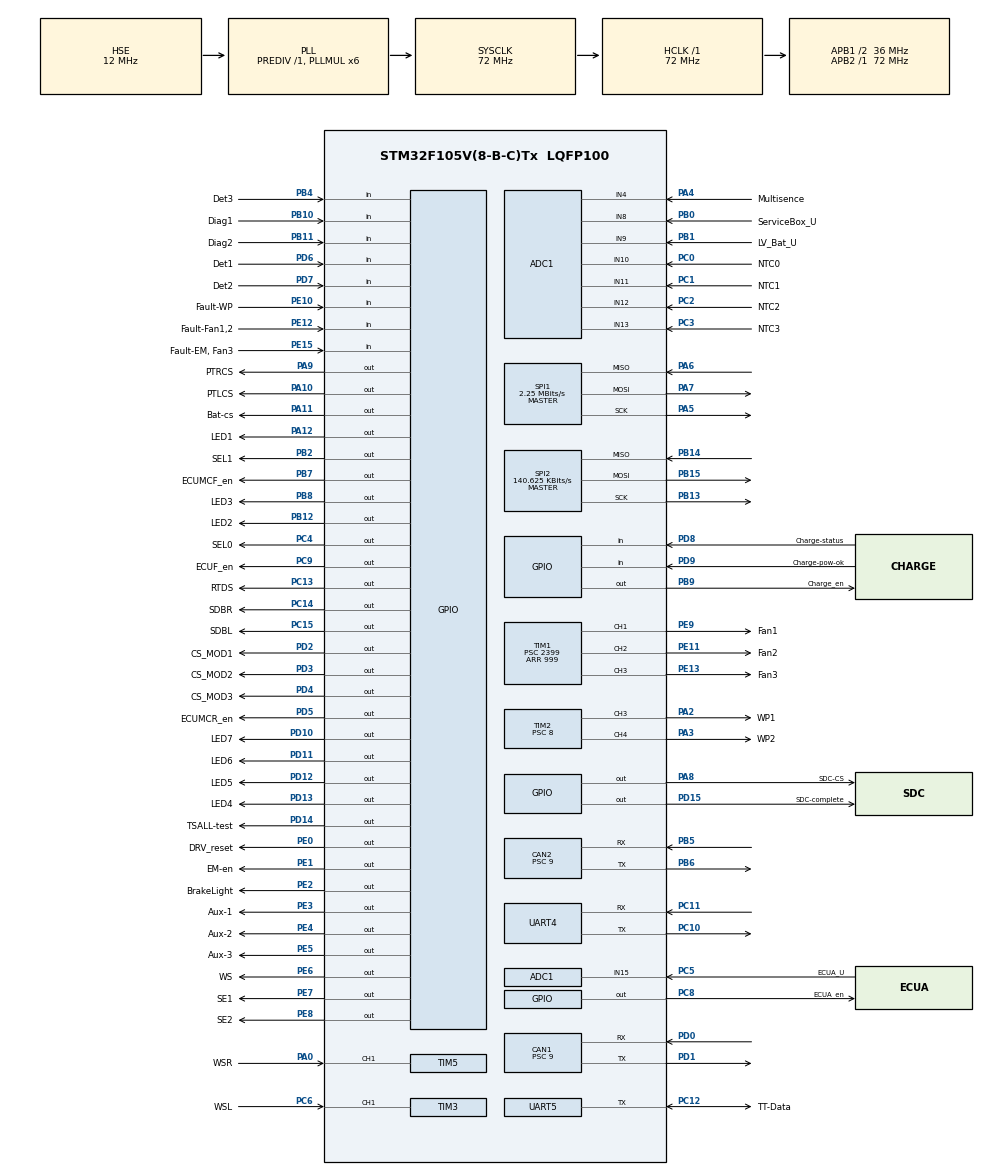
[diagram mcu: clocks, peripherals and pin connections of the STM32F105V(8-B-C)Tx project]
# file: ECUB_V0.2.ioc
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ADC1.Channel-10\#ChannelRegularConversion=ADC_CHANNEL_8
ADC1.Channel-11\#ChannelRegularConversion=ADC_CHANNEL_9
ADC1.Channel-12\#ChannelRegularConversion=ADC_CHANNEL_10
ADC1.Channel-13\#ChannelRegularConversion=ADC_CHANNEL_11
ADC1.Channel-14\#ChannelRegularConversion=ADC_CHANNEL_12
ADC1.Channel-15\#ChannelRegularConversion=ADC_CHANNEL_13
ADC1.Channel-16\#ChannelRegularConversion=ADC_CHANNEL_15
ADC1.Channel-9\#ChannelRegularConversion=ADC_CHANNEL_4
ADC1.ContinuousConvMode=ENABLE
ADC1.DataAlign=ADC_DATAALIGN_RIGHT
ADC1.DiscontinuousConvMode=DISABLE
ADC1.EnableAnalogWatchDog=false
ADC1.EnableRegularConversion=ENABLE
ADC1.ExternalTrigConv=ADC_SOFTWARE_START
ADC1.InjNumberOfConversion=0
ADC1.NbrOfConversion=8
ADC1.NbrOfConversionFlag=1
ADC1.Rank-10\#ChannelRegularConversion=2
ADC1.Rank-11\#ChannelRegularConversion=3
ADC1.Rank-12\#ChannelRegularConversion=4
ADC1.Rank-13\#ChannelRegularConversion=5
ADC1.Rank-14\#ChannelRegularConversion=6
ADC1.Rank-15\#ChannelRegularConversion=7
ADC1.Rank-16\#ChannelRegularConversion=8
ADC1.Rank-9\#ChannelRegularConversion=1
ADC1.SamplingTime-10\#ChannelRegularConversion=ADC_SAMPLETIME_1CYCLE_5
ADC1.SamplingTime-11\#ChannelRegularConversion=ADC_SAMPLETIME_1CYCLE_5
ADC1.SamplingTime-12\#ChannelRegularConversion=ADC_SAMPLETIME_1CYCLE_5
ADC1.SamplingTime-13\#ChannelRegularConversion=ADC_SAMPLETIME_1CYCLE_5
ADC1.SamplingTime-14\#ChannelRegularConversion=ADC_SAMPLETIME_1CYCLE_5
ADC1.SamplingTime-15\#ChannelRegularConversion=ADC_SAMPLETIME_1CYCLE_5
ADC1.SamplingTime-16\#ChannelRegularConversion=ADC_SAMPLETIME_1CYCLE_5
ADC1.SamplingTime-9\#ChannelRegularConversion=ADC_SAMPLETIME_1CYCLE_5
ADC1.ScanConvMode=ADC_SCAN_ENABLE
ADC1.master=1
CAN1.ABOM=ENABLE
CAN1.BS1=CAN_BS1_6TQ
CAN1.CalculateTimeBit=750
CAN1.CalculateTimeQuantum=250.0
CAN1.Mode=CAN_MODE_NORMAL
CAN1.Prescaler=9
CAN2.ABOM=ENABLE
CAN2.BS1=CAN_BS1_6TQ
CAN2.CalculateTimeBit=750
CAN2.CalculateTimeQuantum=250.0
CAN2.Mode=CAN_MODE_NORMAL
CAN2.Prescaler=9
Dma.ADC1.0.Direction=DMA_PERIPH_TO_MEMORY
Dma.ADC1.0.Instance=DMA1_Channel1
Dma.ADC1.0.MemDataAlignment=DMA_MDATAALIGN_HALFWORD
Dma.ADC1.0.MemInc=DMA_MINC_ENABLE
Dma.ADC1.0.Mode=DMA_CIRCULAR
Dma.ADC1.0.PeriphDataAlignment=DMA_PDATAALIGN_HALFWORD
Dma.ADC1.0.PeriphInc=DMA_PINC_DISABLE
Dma.ADC1.0.Priority=DMA_PRIORITY_HIGH
Dma.Request0=ADC1
Mcu.Family=STM32F1
Mcu.Name=STM32F105V(8-B-C)Tx
Mcu.Package=LQFP100
NVIC.CAN1_RX0_IRQn=true\:0\:0\:false\:false\:true\:true
NVIC.CAN1_RX1_IRQn=true\:0\:0\:false\:false\:true\:true
NVIC.CAN1_SCE_IRQn=true\:0\:0\:false\:false\:true\:true
NVIC.CAN1_TX_IRQn=true\:0\:0\:false\:false\:true\:true
NVIC.CAN2_RX0_IRQn=true\:0\:0\:false\:false\:true\:true
NVIC.CAN2_RX1_IRQn=true\:0\:0\:false\:false\:true\:true
NVIC.CAN2_SCE_IRQn=true\:0\:0\:false\:false\:true\:true
NVIC.CAN2_TX_IRQn=true\:0\:0\:false\:false\:true\:true
NVIC.DMA1_Channel1_IRQn=true\:0\:0\:false\:false\:true\:false
NVIC.PriorityGroup=NVIC_PRIORITYGROUP_4
NVIC.TIM1_BRK_IRQn=true\:0\:0\:false\:false\:true\:true
NVIC.TIM1_CC_IRQn=true\:0\:0\:false\:false\:true\:true
NVIC.TIM1_TRG_COM_IRQn=true\:0\:0\:false\:false\:true\:true
NVIC.TIM1_UP_IRQn=true\:0\:0\:false\:false\:true\:true
NVIC.TIM3_IRQn=true\:0\:0\:false\:false\:true\:true
NVIC.TIM5_IRQn=true\:0\:0\:false\:false\:true\:true
OSC_IN.Mode=HSE-External-Oscillator
OSC_IN.Signal=RCC_OSC_IN
OSC_OUT.Mode=HSE-External-Oscillator
OSC_OUT.Signal=RCC_OSC_OUT
PA0-WKUP.GPIO_Label=WSR
PA0-WKUP.Signal=S_TIM5_CH1
PA10.GPIO_Label=PTLCS
PA10.Signal=GPIO_Output
PA11.GPIO_Label=Bat-cs
PA11.Signal=GPIO_Output
PA12.GPIO_Label=LED1
PA12.Signal=GPIO_Output
PA13.GPIO_Label=SWDIO
PA13.Mode=Trace_Asynchronous_SW
PA13.Signal=SYS_JTMS-SWDIO
PA14.GPIO_Label=SWCLK
PA14.Mode=Trace_Asynchronous_SW
PA14.Signal=SYS_JTCK-SWCLK
PA2.GPIO_Label=WP1
PA2.Signal=S_TIM2_CH3
PA3.GPIO_Label=WP2
PA3.Signal=S_TIM2_CH4
PA4.GPIO_Label=Multisence
PA4.Signal=ADCx_IN4
PA5.Mode=Full_Duplex_Master
PA5.Signal=SPI1_SCK
PA6.Mode=Full_Duplex_Master
PA6.Signal=SPI1_MISO
PA7.Mode=Full_Duplex_Master
PA7.Signal=SPI1_MOSI
PA8.GPIO_Label=SDC-CS
PA8.Signal=GPIO_Output
PA9.GPIO_Label=PTRCS
PA9.Signal=GPIO_Output
PB0.GPIO_Label=ServiceBox_U
PB0.Signal=ADCx_IN8
PB1.GPIO_Label=LV_Bat_U
PB1.Signal=ADCx_IN9
PB10.GPIO_Label=Diag1
PB10.Signal=GPIO_Input
PB11.GPIO_Label=Diag2
PB11.Signal=GPIO_Input
PB12.GPIO_Label=LED2
PB12.Signal=GPIO_Output
PB13.Mode=Full_Duplex_Master
PB13.Signal=SPI2_SCK
PB14.Mode=Full_Duplex_Master
PB14.Signal=SPI2_MISO
PB15.Mode=Full_Duplex_Master
PB15.Signal=SPI2_MOSI
PB2.GPIO_Label=SEL1
PB2.Signal=GPIO_Output
PB3.GPIO_Label=SWO
PB3.Mode=Trace_Asynchronous_SW
PB3.Signal=SYS_TRACESWO
PB4.GPIO_Label=Det3
PB4.Signal=GPIO_Input
PB5.Mode=Slave
PB5.Signal=CAN2_RX
PB6.Mode=Slave
PB6.Signal=CAN2_TX
PB7.GPIO_Label=ECUMCF_en
PB7.Signal=GPIO_Output
PB8.GPIO_Label=LED3
PB8.Signal=GPIO_Output
PB9.GPIO_Label=Charge_en
PB9.Signal=GPIO_Output
PC0.GPIO_Label=NTC0
PC0.Signal=ADCx_IN10
PC1.GPIO_Label=NTC1
PC1.Signal=ADCx_IN11
PC10.Mode=Asynchronous
PC10.Signal=UART4_TX
PC11.Mode=Asynchronous
PC11.Signal=UART4_RX
PC12.GPIO_Label=TT-Data
PC12.Mode=Half_duplex(single_wire_mode)
PC12.Signal=UART5_TX
PC13-TAMPER-RTC.GPIO_Label=RTDS
PC13-TAMPER-RTC.Signal=GPIO_Output
PC14-OSC32_IN.GPIO_Label=SDBR
PC14-OSC32_IN.Signal=GPIO_Output
PC15-OSC32_OUT.GPIO_Label=SDBL
PC15-OSC32_OUT.Signal=GPIO_Output
PC2.GPIO_Label=NTC2
PC2.Signal=ADCx_IN12
PC3.GPIO_Label=NTC3
PC3.Signal=ADCx_IN13
PC4.GPIO_Label=SEL0
PC4.Signal=GPIO_Output
PC5.GPIO_Label=ECUA_U
PC5.Signal=ADCx_IN15
PC6.GPIO_Label=WSL
PC6.Signal=S_TIM3_CH1
PC8.GPIO_Label=ECUA_en
PC8.Signal=GPIO_Output
PC9.GPIO_Label=ECUF_en
PC9.Signal=GPIO_Output
PD0.Mode=Master
PD0.Signal=CAN1_RX
PD1.Mode=Master
PD1.Signal=CAN1_TX
PD10.GPIO_Label=LED7
PD10.Signal=GPIO_Output
PD11.GPIO_Label=LED6
PD11.Signal=GPIO_Output
PD12.GPIO_Label=LED5
PD12.Signal=GPIO_Output
PD13.GPIO_Label=LED4
PD13.Signal=GPIO_Output
PD14.GPIO_Label=TSALL-test
PD14.Signal=GPIO_Output
PD15.GPIO_Label=SDC-complete
PD15.Signal=GPIO_Output
PD2.GPIO_Label=CS_MOD1
PD2.Signal=GPIO_Output
PD3.GPIO_Label=CS_MOD2
PD3.Signal=GPIO_Output
PD4.GPIO_Label=CS_MOD3
PD4.Signal=GPIO_Output
PD5.GPIO_Label=ECUMCR_en
PD5.Signal=GPIO_Output
PD6.GPIO_Label=Det1
PD6.Signal=GPIO_Input
PD7.GPIO_Label=Det2
PD7.Signal=GPIO_Input
PD8.GPIO_Label=Charge-status
PD8.Signal=GPIO_Input
PD9.GPIO_Label=Charge-pow-ok
PD9.Signal=GPIO_Input
PE0.GPIO_Label=DRV_reset
PE0.Signal=GPIO_Output
PE1.GPIO_Label=EM-en
PE1.Signal=GPIO_Output
PE10.GPIO_Label=Fault-WP
PE10.Signal=GPIO_Input
PE11.GPIO_Label=Fan2
PE11.Signal=S_TIM1_CH2
PE12.GPIO_Label=Fault-Fan1,2
PE12.Signal=GPIO_Input
PE13.GPIO_Label=Fan3
PE13.Signal=S_TIM1_CH3
PE15.GPIO_Label=Fault-EM, Fan3
PE15.Signal=GPIO_Input
PE2.GPIO_Label=BrakeLight
PE2.Signal=GPIO_Output
PE3.GPIO_Label=Aux-1
PE3.Signal=GPIO_Output
PE4.GPIO_Label=Aux-2
PE4.Signal=GPIO_Output
PE5.GPIO_Label=Aux-3
PE5.Signal=GPIO_Output
PE6.GPIO_Label=WS
PE6.Signal=GPIO_Output
PE7.GPIO_Label=SE1
PE7.Signal=GPIO_Output
PE8.GPIO_Label=SE2
PE8.Signal=GPIO_Output
PE9.GPIO_Label=Fan1
PE9.Signal=S_TIM1_CH1
ProjectManager.HeapSize=0x200
ProjectManager.StackSize=0x400
ProjectManager.TargetToolchain=MDK-ARM V5
RCC.ADCPresc=RCC_ADCPCLK2_DIV6
RCC.AHBFreq_Value=72000000
RCC.APB1CLKDivider=RCC_HCLK_DIV2
RCC.APB1Freq_Value=36000000
RCC.APB1TimFreq_Value=72000000
RCC.APB2Freq_Value=72000000
RCC.APB2TimFreq_Value=72000000
RCC.HCLKFreq_Value=72000000
RCC.HSE_VALUE=12000000
RCC.PLLMUL=RCC_PLL_MUL6
RCC.PLLSourceVirtual=RCC_PLLSOURCE_HSE
RCC.SYSCLKFreq_VALUE=72000000
RCC.SYSCLKSource=RCC_SYSCLKSOURCE_PLLCLK
RCC.USBFreq_Value=48000000
SH.ADCx_IN10.0=ADC1_IN10,IN10
SH.ADCx_IN11.0=ADC1_IN11,IN11
SH.ADCx_IN12.0=ADC1_IN12,IN12
SH.ADCx_IN13.0=ADC1_IN13,IN13
SH.ADCx_IN15.0=ADC1_IN15,IN15
SH.ADCx_IN4.0=ADC1_IN4,IN4
SH.ADCx_IN8.0=ADC1_IN8,IN8
SH.ADCx_IN9.0=ADC1_IN9,IN9
SH.S_TIM1_CH1.0=TIM1_CH1,PWM Generation1 CH1
SH.S_TIM1_CH2.0=TIM1_CH2,PWM Generation2 CH2
SH.S_TIM1_CH3.0=TIM1_CH3,PWM Generation3 CH3
SH.S_TIM2_CH3.0=TIM2_CH3,PWM Generation3 CH3
SH.S_TIM2_CH4.0=TIM2_CH4,PWM Generation4 CH4
SH.S_TIM3_CH1.0=TIM3_CH1,Input_Capture1_from_TI1
SH.S_TIM5_CH1.0=TIM5_CH1,Input_Capture1_from_TI1
SPI1.BaudRatePrescaler=SPI_BAUDRATEPRESCALER_32
SPI1.CalculateBaudRate=2.25 MBits/s
SPI1.Direction=SPI_DIRECTION_2LINES
SPI1.Mode=SPI_MODE_MASTER
SPI1.VirtualType=VM_MASTER
SPI2.BaudRatePrescaler=SPI_BAUDRATEPRESCALER_256
SPI2.CalculateBaudRate=140.625 KBits/s
SPI2.DataSize=SPI_DATASIZE_16BIT
SPI2.Direction=SPI_DIRECTION_2LINES
SPI2.Mode=SPI_MODE_MASTER
SPI2.VirtualType=VM_MASTER
TIM1.Channel-PWM\ Generation1\ CH1=TIM_CHANNEL_1
TIM1.Channel-PWM\ Generation2\ CH2=TIM_CHANNEL_2
TIM1.Channel-PWM\ Generation3\ CH3=TIM_CHANNEL_3
TIM1.Period=999
TIM1.Prescaler=2399
TIM2.Channel-PWM\ Generation3\ CH3=TIM_CHANNEL_3
TIM2.Channel-PWM\ Generation4\ CH4=TIM_CHANNEL_4
TIM2.Period=999
TIM2.Prescaler=8
TIM3.Channel-Input_Capture1_from_TI1=TIM_CHANNEL_1
TIM3.Period=0xFFFF
TIM3.Prescaler=72
TIM5.Channel-Input_Capture1_from_TI1=TIM_CHANNEL_1
TIM5.Period=0xFFFF
TIM5.Prescaler=72
UART4.VirtualMode=Asynchronous
UART5.VirtualMode=Asynchronous
VP_TIM1_VS_ClockSourceINT.Mode=Internal
VP_TIM2_VS_ClockSourceINT.Mode=Internal
VP_TIM3_VS_ClockSourceINT.Mode=Internal
VP_TIM5_VS_ClockSourceINT.Mode=Internal
board=ECUB_V0.2

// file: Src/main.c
/**
  ******************************************************************************
  * @file           : main.c
  * @brief          : Main program body
  ******************************************************************************
  ******************************************************************************
  */
#include "main.h"
#include "stm32f1xx_hal.h"
#include "ltc6804.h"

/* USER CODE BEGIN Includes */
#include "carstate.h"
#include "tx2/can.h"
#include "ADC.h"
#include "can_eforce_init.h"
#include "Wheel_speed.h"
#include "can_ECUB.h"
#include "cooling_circuit.h"
#include "Brake_Sensors.h"
#include "LvBattery.h"
/* USER CODE END Includes */

ADC_HandleTypeDef hadc1;
DMA_HandleTypeDef hdma_adc1;

CAN_HandleTypeDef hcan1;
CAN_HandleTypeDef hcan2;

SPI_HandleTypeDef hspi1;
SPI_HandleTypeDef hspi2;

TIM_HandleTypeDef htim1;
TIM_HandleTypeDef htim2;
TIM_HandleTypeDef htim3;
TIM_HandleTypeDef htim5;

UART_HandleTypeDef huart4;
UART_HandleTypeDef huart5;

/* USER CODE BEGIN PV */
/* Private variables ---------------------------------------------------------*/
CanRxMsgTypeDef canRxMsg1; //can1 structure for reciving raw data
CanRxMsgTypeDef canRxMsg2; //can2 structure for reciving raw data
ECUB_Power_dist_t ECUB_POW; //can structure for sending data
/* USER CODE END PV */

void SystemClock_Config(void);
static void MX_GPIO_Init(void);
static void MX_DMA_Init(void);
static void MX_ADC1_Init(void);
static void MX_CAN1_Init(void);
static void MX_CAN2_Init(void);
static void MX_SPI1_Init(void);
static void MX_SPI2_Init(void);
static void MX_TIM1_Init(void);
static void MX_UART4_Init(void);
static void MX_UART5_Init(void);
static void MX_TIM2_Init(void);
static void MX_TIM5_Init(void);
static void MX_TIM3_Init(void);

void HAL_TIM_MspPostInit(TIM_HandleTypeDef *htim);

/* USER CODE BEGIN PFP */
/* Private function prototypes -----------------------------------------------*/

/* USER CODE END PFP */

/* USER CODE BEGIN 0 */
/*void HAL_CAN_RxCpltCallback(CAN_HandleTypeDef* hcan){	//callback for reciving can data
	HAL_GPIO_TogglePin(LED5_GPIO_Port,LED5_Pin); //toggles led every times something is recived from can
	if (hcan->Instance == CAN1){ //callback is called after canRxMsg1 is filled form can1
		txReceiveCANMessage(bus_CAN1_powertrain,canRxMsg1.StdId,&canRxMsg1.Data,canRxMsg1.DLC); //resifre given raw data to candb structures
	}else if(hcan->Instance == CAN2){ //callback is called after canRxMsg1 is filled form can1
		txReceiveCANMessage(bus_CAN2_aux,canRxMsg2.StdId,&canRxMsg2.Data,canRxMsg2.DLC); //resifre given raw data to candb structures
	}
	HAL_CAN_Receive_IT(hcan,CAN_FIFO0);
	__HAL_CAN_FIFO_RELEASE(hcan,CAN_FIFO0); //enables hcan fifo for next reciving
}*/
/* USER CODE END 0 */

int main(void)
{

  /* MCU Configuration----------------------------------------------------------*/

  /* Reset of all peripherals, Initializes the Flash interface and the Systick. */
  HAL_Init();

  /* Configure the system clock */
  SystemClock_Config();

  /* Initialize all configured peripherals */
  MX_GPIO_Init();
  MX_DMA_Init();
  MX_ADC1_Init();
  MX_CAN1_Init();
  MX_CAN2_Init();
  MX_SPI1_Init();
  MX_SPI2_Init();
  MX_TIM1_Init();
  MX_UART4_Init();
  MX_UART5_Init();
  MX_TIM2_Init();
  MX_TIM5_Init();
  MX_TIM3_Init();
  /* USER CODE BEGIN 2 */
	CAN_eforce(&hcan1,CAN1,&canRxMsg1);
	CAN_eforce(&hcan2,CAN2,&canRxMsg2);

	txInit();
	candbInit();
	HAL_GPIO_TogglePin(LED1_GPIO_Port,LED1_Pin);
	HAL_GPIO_TogglePin(LED2_GPIO_Port,LED2_Pin);
	HAL_GPIO_TogglePin(LED3_GPIO_Port,LED3_Pin);
	HAL_GPIO_TogglePin(LED4_GPIO_Port,LED4_Pin);
	HAL_GPIO_TogglePin(LED5_GPIO_Port,LED5_Pin);
	HAL_GPIO_TogglePin(LED6_GPIO_Port,LED6_Pin);
	HAL_GPIO_TogglePin(LED7_GPIO_Port,LED7_Pin);
	carstate_init(); //initial carstate
	start_ADC(&hadc1);
	HAL_SPI_MspInit(&hspi2);
	HAL_GPIO_WritePin(SDC_CS_GPIO_Port,SDC_CS_Pin,GPIO_PIN_SET);
	HAL_GPIO_WritePin(PTRCS_GPIO_Port,PTRCS_Pin,GPIO_PIN_SET); //select chip
	HAL_GPIO_WritePin(PTLCS_GPIO_Port,PTLCS_Pin,GPIO_PIN_SET); //select chip

	HAL_CAN_Receive_IT(&hcan1,CAN_FIFO0);

	//some new spi
	{GPIO_InitTypeDef GPIO_InitStruct;
	GPIO_InitStruct.Pin = SDC_CS_Pin;
	GPIO_InitStruct.Mode = GPIO_MODE_OUTPUT_OD;
	GPIO_InitStruct.Pull = GPIO_NOPULL;
	GPIO_InitStruct.Speed = GPIO_SPEED_FREQ_MEDIUM;
  HAL_GPIO_Init(SDC_CS_GPIO_Port, &GPIO_InitStruct);}

	{GPIO_InitTypeDef GPIO_InitStruct;
	GPIO_InitStruct.Pin = Charge_status_Pin;
	GPIO_InitStruct.Mode = GPIO_MODE_INPUT;
	GPIO_InitStruct.Pull = GPIO_PULLUP;
	GPIO_InitStruct.Speed = GPIO_SPEED_FREQ_MEDIUM;
  HAL_GPIO_Init(Charge_status_GPIO_Port, &GPIO_InitStruct);}
	LTC_DRV_SPI_CSHigh();
	{GPIO_InitTypeDef GPIO_InitStruct;
	GPIO_InitStruct.Pin = Bat_cs_Pin;
	GPIO_InitStruct.Mode = GPIO_MODE_OUTPUT_PP;
	GPIO_InitStruct.Pull = GPIO_NOPULL;
	GPIO_InitStruct.Speed = GPIO_SPEED_FREQ_LOW;
  HAL_GPIO_Init(Bat_cs_GPIO_Port, &GPIO_InitStruct);}

	//end of some new spi

	LV_init();
	HAL_GPIO_WritePin(WS_GPIO_Port,WS_Pin,GPIO_PIN_SET); //select chip
	start_PWM(&htim2, &htim1 , get_can_state()); //starts PWM for fans and pumps
	start_WS_measure(&htim5,&htim3); //starts Wheel speed measurement...using DMA...
	brake_sens_init(&hspi1); //init of brake sensors
	while(!units_set(GPIO_PIN_SET,get_can_state())||(!aux_set(GPIO_PIN_SET,get_can_state()))){} //gives power to all units and aux
  /* USER CODE END 2 */

  /* Infinite loop */
  /* USER CODE BEGIN WHILE */
  while (1)
  {
	txProcess(); //translate message
	carstate_process(&hspi2,&hcan1); //entire carstate logic
	Can_WheelSpeed(&hcan1,&htim3,&htim5); //wheelspeed
	cooling_poccess(&htim1,&htim2,&hcan2); //cooling process main function
	pwm_check(get_can_state(),&hcan2); //function sendindg pwm can message
	brake_sens_process(&hspi2,&hcan2); //measuring breake temperatures
	LV_process(&hcan2); //measuring voltages on battery and debug for charging
	if(ECUB_Power_dist_need_to_send()){
		ECUB_send_Power_dist_s(&ECUB_POW);
		HAL_CAN_Receive_IT(&hcan2,CAN_FIFO0);
	}

  /* USER CODE END WHILE */

  }

}

void SystemClock_Config(void)
{

  RCC_OscInitTypeDef RCC_OscInitStruct;
  RCC_ClkInitTypeDef RCC_ClkInitStruct;
  RCC_PeriphCLKInitTypeDef PeriphClkInit;

    /**Initializes the CPU, AHB and APB busses clocks
    */
  RCC_OscInitStruct.OscillatorType = RCC_OSCILLATORTYPE_HSE;
  RCC_OscInitStruct.HSEState = RCC_HSE_ON;
  RCC_OscInitStruct.HSEPredivValue = RCC_HSE_PREDIV_DIV1;
  RCC_OscInitStruct.HSIState = RCC_HSI_ON;
  RCC_OscInitStruct.Prediv1Source = RCC_PREDIV1_SOURCE_HSE;
  RCC_OscInitStruct.PLL.PLLState = RCC_PLL_ON;
  RCC_OscInitStruct.PLL.PLLSource = RCC_PLLSOURCE_HSE;
  RCC_OscInitStruct.PLL.PLLMUL = RCC_PLL_MUL6;
  RCC_OscInitStruct.PLL2.PLL2State = RCC_PLL_NONE;
  if (HAL_RCC_OscConfig(&RCC_OscInitStruct) != HAL_OK)
  {
    _Error_Handler(__FILE__, __LINE__);
  }

    /**Initializes the CPU, AHB and APB busses clocks
    */
  RCC_ClkInitStruct.ClockType = RCC_CLOCKTYPE_HCLK|RCC_CLOCKTYPE_SYSCLK
                              |RCC_CLOCKTYPE_PCLK1|RCC_CLOCKTYPE_PCLK2;
  RCC_ClkInitStruct.SYSCLKSource = RCC_SYSCLKSOURCE_PLLCLK;
  RCC_ClkInitStruct.AHBCLKDivider = RCC_SYSCLK_DIV1;
  RCC_ClkInitStruct.APB1CLKDivider = RCC_HCLK_DIV2;
  RCC_ClkInitStruct.APB2CLKDivider = RCC_HCLK_DIV1;

  if (HAL_RCC_ClockConfig(&RCC_ClkInitStruct, FLASH_LATENCY_2) != HAL_OK)
  {
    _Error_Handler(__FILE__, __LINE__);
  }

  PeriphClkInit.PeriphClockSelection = RCC_PERIPHCLK_ADC;
  PeriphClkInit.AdcClockSelection = RCC_ADCPCLK2_DIV6;
  if (HAL_RCCEx_PeriphCLKConfig(&PeriphClkInit) != HAL_OK)
  {
    _Error_Handler(__FILE__, __LINE__);
  }

    /**Configure the Systick interrupt time
    */
  HAL_SYSTICK_Config(HAL_RCC_GetHCLKFreq()/1000);

    /**Configure the Systick
    */
  HAL_SYSTICK_CLKSourceConfig(SYSTICK_CLKSOURCE_HCLK);

    /**Configure the Systick interrupt time
    */
  __HAL_RCC_PLLI2S_ENABLE();

  /* SysTick_IRQn interrupt configuration */
  HAL_NVIC_SetPriority(SysTick_IRQn, 0, 0);
}

/* ADC1 init function */
static void MX_ADC1_Init(void)
{

  ADC_ChannelConfTypeDef sConfig;

    /**Common config
    */
  hadc1.Instance = ADC1;
  hadc1.Init.ScanConvMode = ADC_SCAN_ENABLE;
  hadc1.Init.ContinuousConvMode = ENABLE;
  hadc1.Init.DiscontinuousConvMode = DISABLE;
  hadc1.Init.ExternalTrigConv = ADC_SOFTWARE_START;
  hadc1.Init.DataAlign = ADC_DATAALIGN_RIGHT;
  hadc1.Init.NbrOfConversion = 9;
  if (HAL_ADC_Init(&hadc1) != HAL_OK)
  {
    _Error_Handler(__FILE__, __LINE__);
  }

    /**Configure Regular Channel
    */
  sConfig.Channel = ADC_CHANNEL_4;
  sConfig.Rank = ADC_REGULAR_RANK_1;
  sConfig.SamplingTime = ADC_SAMPLETIME_1CYCLE_5;
  if (HAL_ADC_ConfigChannel(&hadc1, &sConfig) != HAL_OK)
  {
    _Error_Handler(__FILE__, __LINE__);
  }

    /**Configure Regular Channel
    */
  sConfig.Channel = ADC_CHANNEL_8;
  sConfig.Rank = ADC_REGULAR_RANK_2;
  if (HAL_ADC_ConfigChannel(&hadc1, &sConfig) != HAL_OK)
  {
    _Error_Handler(__FILE__, __LINE__);
  }

    /**Configure Regular Channel
    */
  sConfig.Channel = ADC_CHANNEL_9;
  sConfig.Rank = ADC_REGULAR_RANK_3;
  if (HAL_ADC_ConfigChannel(&hadc1, &sConfig) != HAL_OK)
  {
    _Error_Handler(__FILE__, __LINE__);
  }

    /**Configure Regular Channel
    */
  sConfig.Channel = ADC_CHANNEL_10;
  sConfig.Rank = ADC_REGULAR_RANK_4;
  if (HAL_ADC_ConfigChannel(&hadc1, &sConfig) != HAL_OK)
  {
    _Error_Handler(__FILE__, __LINE__);
  }

    /**Configure Regular Channel
    */
  sConfig.Channel = ADC_CHANNEL_11;
  sConfig.Rank = ADC_REGULAR_RANK_5;
  if (HAL_ADC_ConfigChannel(&hadc1, &sConfig) != HAL_OK)
  {
    _Error_Handler(__FILE__, __LINE__);
  }

    /**Configure Regular Channel
    */
  sConfig.Channel = ADC_CHANNEL_12;
  sConfig.Rank = ADC_REGULAR_RANK_6;
  if (HAL_ADC_ConfigChannel(&hadc1, &sConfig) != HAL_OK)
  {
    _Error_Handler(__FILE__, __LINE__);
  }

    /**Configure Regular Channel
    */
  sConfig.Channel = ADC_CHANNEL_13;
  sConfig.Rank = ADC_REGULAR_RANK_7;
  if (HAL_ADC_ConfigChannel(&hadc1, &sConfig) != HAL_OK)
  {
    _Error_Handler(__FILE__, __LINE__);
  }

    /**Configure Regular Channel
    */
  sConfig.Channel = ADC_CHANNEL_15;
  sConfig.Rank = ADC_REGULAR_RANK_8;
  if (HAL_ADC_ConfigChannel(&hadc1, &sConfig) != HAL_OK)
  {
    _Error_Handler(__FILE__, __LINE__);
  }
	sConfig.Channel = ADC_CHANNEL_TEMPSENSOR;
  sConfig.Rank = ADC_REGULAR_RANK_9;
  if (HAL_ADC_ConfigChannel(&hadc1, &sConfig) != HAL_OK)
  {
    _Error_Handler(__FILE__, __LINE__);
  }
}

/* CAN1 init function */
static void MX_CAN1_Init(void)
{

  hcan1.Instance = CAN1;
  hcan1.Init.Prescaler = 9;
  hcan1.Init.Mode = CAN_MODE_NORMAL;
  hcan1.Init.SJW = CAN_SJW_1TQ;
  hcan1.Init.BS1 = CAN_BS1_6TQ;
  hcan1.Init.BS2 = CAN_BS2_1TQ;
  hcan1.Init.TTCM = DISABLE;
  hcan1.Init.ABOM = ENABLE;
  hcan1.Init.AWUM = DISABLE;
  hcan1.Init.NART = DISABLE;
  hcan1.Init.RFLM = DISABLE;
  hcan1.Init.TXFP = DISABLE;
  if (HAL_CAN_Init(&hcan1) != HAL_OK)
  {
    _Error_Handler(__FILE__, __LINE__);
  }

}

/* CAN2 init function */
static void MX_CAN2_Init(void)
{

  hcan2.Instance = CAN2;
  hcan2.Init.Prescaler = 9;
  hcan2.Init.Mode = CAN_MODE_NORMAL;
  hcan2.Init.SJW = CAN_SJW_1TQ;
  hcan2.Init.BS1 = CAN_BS1_6TQ;
  hcan2.Init.BS2 = CAN_BS2_1TQ;
  hcan2.Init.TTCM = DISABLE;
  hcan2.Init.ABOM = ENABLE;
  hcan2.Init.AWUM = DISABLE;
  hcan2.Init.NART = DISABLE;
  hcan2.Init.RFLM = DISABLE;
  hcan2.Init.TXFP = DISABLE;
  if (HAL_CAN_Init(&hcan2) != HAL_OK)
  {
    _Error_Handler(__FILE__, __LINE__);
  }

}

/* SPI1 init function */
static void MX_SPI1_Init(void)
{

  /* SPI1 parameter configuration*/
  hspi1.Instance = SPI1;
  hspi1.Init.Mode = SPI_MODE_MASTER;
  hspi1.Init.Direction = SPI_DIRECTION_2LINES;
  hspi1.Init.DataSize = SPI_DATASIZE_8BIT;
  hspi1.Init.CLKPolarity = SPI_POLARITY_LOW;
  hspi1.Init.CLKPhase = SPI_PHASE_1EDGE;
  hspi1.Init.NSS = SPI_NSS_SOFT;
  hspi1.Init.BaudRatePrescaler = SPI_BAUDRATEPRESCALER_32;
  hspi1.Init.FirstBit = SPI_FIRSTBIT_MSB;
  hspi1.Init.TIMode = SPI_TIMODE_DISABLE;
  hspi1.Init.CRCCalculation = SPI_CRCCALCULATION_DISABLE;
  hspi1.Init.CRCPolynomial = 10;
  if (HAL_SPI_Init(&hspi1) != HAL_OK)
  {
    _Error_Handler(__FILE__, __LINE__);
  }

}

/* SPI2 init function */
static void MX_SPI2_Init(void)
{

  /* SPI2 parameter configuration*/
  hspi2.Instance = SPI2;
  hspi2.Init.Mode = SPI_MODE_MASTER;
  hspi2.Init.Direction = SPI_DIRECTION_2LINES;
  hspi2.Init.DataSize = SPI_DATASIZE_16BIT;
  hspi2.Init.CLKPolarity = SPI_POLARITY_LOW;
  hspi2.Init.CLKPhase = SPI_PHASE_1EDGE;
  hspi2.Init.NSS = SPI_NSS_SOFT;
  hspi2.Init.BaudRatePrescaler = SPI_BAUDRATEPRESCALER_256;
  hspi2.Init.FirstBit = SPI_FIRSTBIT_MSB;
  hspi2.Init.TIMode = SPI_TIMODE_DISABLE;
  hspi2.Init.CRCCalculation = SPI_CRCCALCULATION_DISABLE;
  hspi2.Init.CRCPolynomial = 10;
  if (HAL_SPI_Init(&hspi2) != HAL_OK)
  {
    _Error_Handler(__FILE__, __LINE__);
  }

}

/* TIM1 init function */
static void MX_TIM1_Init(void)
{

  TIM_ClockConfigTypeDef sClockSourceConfig;
  TIM_MasterConfigTypeDef sMasterConfig;
  TIM_OC_InitTypeDef sConfigOC;
  TIM_BreakDeadTimeConfigTypeDef sBreakDeadTimeConfig;

  htim1.Instance = TIM1;
  htim1.Init.Prescaler = 2399;
  htim1.Init.CounterMode = TIM_COUNTERMODE_UP;
  htim1.Init.Period = 999;
  htim1.Init.ClockDivision = TIM_CLOCKDIVISION_DIV1;
  htim1.Init.RepetitionCounter = 0;
  htim1.Init.AutoReloadPreload = TIM_AUTORELOAD_PRELOAD_DISABLE;
  if (HAL_TIM_Base_Init(&htim1) != HAL_OK)
  {
    _Error_Handler(__FILE__, __LINE__);
  }

  sClockSourceConfig.ClockSource = TIM_CLOCKSOURCE_INTERNAL;
  if (HAL_TIM_ConfigClockSource(&htim1, &sClockSourceConfig) != HAL_OK)
  {
    _Error_Handler(__FILE__, __LINE__);
  }

  if (HAL_TIM_PWM_Init(&htim1) != HAL_OK)
  {
    _Error_Handler(__FILE__, __LINE__);
  }

  sMasterConfig.MasterOutputTrigger = TIM_TRGO_RESET;
  sMasterConfig.MasterSlaveMode = TIM_MASTERSLAVEMODE_DISABLE;
  if (HAL_TIMEx_MasterConfigSynchronization(&htim1, &sMasterConfig) != HAL_OK)
  {
    _Error_Handler(__FILE__, __LINE__);
  }

  sConfigOC.OCMode = TIM_OCMODE_PWM1;
  sConfigOC.Pulse = 0;
  sConfigOC.OCPolarity = TIM_OCPOLARITY_HIGH;
  sConfigOC.OCNPolarity = TIM_OCNPOLARITY_HIGH;
  sConfigOC.OCFastMode = TIM_OCFAST_DISABLE;
  sConfigOC.OCIdleState = TIM_OCIDLESTATE_RESET;
  sConfigOC.OCNIdleState = TIM_OCNIDLESTATE_RESET;
  if (HAL_TIM_PWM_ConfigChannel(&htim1, &sConfigOC, TIM_CHANNEL_1) != HAL_OK)
  {
    _Error_Handler(__FILE__, __LINE__);
  }

  if (HAL_TIM_PWM_ConfigChannel(&htim1, &sConfigOC, TIM_CHANNEL_2) != HAL_OK)
  {
    _Error_Handler(__FILE__, __LINE__);
  }

  if (HAL_TIM_PWM_ConfigChannel(&htim1, &sConfigOC, TIM_CHANNEL_3) != HAL_OK)
  {
    _Error_Handler(__FILE__, __LINE__);
  }

  sBreakDeadTimeConfig.OffStateRunMode = TIM_OSSR_DISABLE;
  sBreakDeadTimeConfig.OffStateIDLEMode = TIM_OSSI_DISABLE;
  sBreakDeadTimeConfig.LockLevel = TIM_LOCKLEVEL_OFF;
  sBreakDeadTimeConfig.DeadTime = 0;
  sBreakDeadTimeConfig.BreakState = TIM_BREAK_DISABLE;
  sBreakDeadTimeConfig.BreakPolarity = TIM_BREAKPOLARITY_HIGH;
  sBreakDeadTimeConfig.AutomaticOutput = TIM_AUTOMATICOUTPUT_DISABLE;
  if (HAL_TIMEx_ConfigBreakDeadTime(&htim1, &sBreakDeadTimeConfig) != HAL_OK)
  {
    _Error_Handler(__FILE__, __LINE__);
  }

  HAL_TIM_MspPostInit(&htim1);

}

/* TIM2 init function */
static void MX_TIM2_Init(void)
{

  TIM_ClockConfigTypeDef sClockSourceConfig;
  TIM_MasterConfigTypeDef sMasterConfig;
  TIM_OC_InitTypeDef sConfigOC;

  htim2.Instance = TIM2;
  htim2.Init.Prescaler = 8;
  htim2.Init.CounterMode = TIM_COUNTERMODE_UP;
  htim2.Init.Period = 999;
  htim2.Init.ClockDivision = TIM_CLOCKDIVISION_DIV1;
  htim2.Init.AutoReloadPreload = TIM_AUTORELOAD_PRELOAD_DISABLE;
  if (HAL_TIM_Base_Init(&htim2) != HAL_OK)
  {
    _Error_Handler(__FILE__, __LINE__);
  }

  sClockSourceConfig.ClockSource = TIM_CLOCKSOURCE_INTERNAL;
  if (HAL_TIM_ConfigClockSource(&htim2, &sClockSourceConfig) != HAL_OK)
  {
    _Error_Handler(__FILE__, __LINE__);
  }

  if (HAL_TIM_PWM_Init(&htim2) != HAL_OK)
  {
    _Error_Handler(__FILE__, __LINE__);
  }

  sMasterConfig.MasterOutputTrigger = TIM_TRGO_RESET;
  sMasterConfig.MasterSlaveMode = TIM_MASTERSLAVEMODE_DISABLE;
  if (HAL_TIMEx_MasterConfigSynchronization(&htim2, &sMasterConfig) != HAL_OK)
  {
    _Error_Handler(__FILE__, __LINE__);
  }

  sConfigOC.OCMode = TIM_OCMODE_PWM1;
  sConfigOC.Pulse = 0;
  sConfigOC.OCPolarity = TIM_OCPOLARITY_HIGH;
  sConfigOC.OCFastMode = TIM_OCFAST_DISABLE;
  if (HAL_TIM_PWM_ConfigChannel(&htim2, &sConfigOC, TIM_CHANNEL_3) != HAL_OK)
  {
    _Error_Handler(__FILE__, __LINE__);
  }

  if (HAL_TIM_PWM_ConfigChannel(&htim2, &sConfigOC, TIM_CHANNEL_4) != HAL_OK)
  {
    _Error_Handler(__FILE__, __LINE__);
  }

  HAL_TIM_MspPostInit(&htim2);

}

/* TIM3 init function */
static void MX_TIM3_Init(void)
{

  TIM_ClockConfigTypeDef sClockSourceConfig;
  TIM_MasterConfigTypeDef sMasterConfig;
  TIM_IC_InitTypeDef sConfigIC;

  htim3.Instance = TIM3;
  htim3.Init.Prescaler = 71;
  htim3.Init.CounterMode = TIM_COUNTERMODE_UP;
  htim3.Init.Period = 0xFFFF;
  htim3.Init.ClockDivision = TIM_CLOCKDIVISION_DIV1;
  htim3.Init.AutoReloadPreload = TIM_AUTORELOAD_PRELOAD_DISABLE;
  if (HAL_TIM_Base_Init(&htim3) != HAL_OK)
  {
    _Error_Handler(__FILE__, __LINE__);
  }

  sClockSourceConfig.ClockSource = TIM_CLOCKSOURCE_INTERNAL;
  if (HAL_TIM_ConfigClockSource(&htim3, &sClockSourceConfig) != HAL_OK)
  {
    _Error_Handler(__FILE__, __LINE__);
  }

  if (HAL_TIM_IC_Init(&htim3) != HAL_OK)
  {
    _Error_Handler(__FILE__, __LINE__);
  }

  sMasterConfig.MasterOutputTrigger = TIM_TRGO_RESET;
  sMasterConfig.MasterSlaveMode = TIM_MASTERSLAVEMODE_DISABLE;
  if (HAL_TIMEx_MasterConfigSynchronization(&htim3, &sMasterConfig) != HAL_OK)
  {
    _Error_Handler(__FILE__, __LINE__);
  }

  sConfigIC.ICPolarity = TIM_INPUTCHANNELPOLARITY_RISING;
  sConfigIC.ICSelection = TIM_ICSELECTION_DIRECTTI;
  sConfigIC.ICPrescaler = TIM_ICPSC_DIV1;
  sConfigIC.ICFilter = 0;
  if (HAL_TIM_IC_ConfigChannel(&htim3, &sConfigIC, TIM_CHANNEL_1) != HAL_OK)
  {
    _Error_Handler(__FILE__, __LINE__);
  }

}

/* TIM5 init function */
static void MX_TIM5_Init(void)
{

  TIM_ClockConfigTypeDef sClockSourceConfig;
  TIM_MasterConfigTypeDef sMasterConfig;
  TIM_IC_InitTypeDef sConfigIC;

  htim5.Instance = TIM5;
  htim5.Init.Prescaler = 71;
  htim5.Init.CounterMode = TIM_COUNTERMODE_UP;
  htim5.Init.Period = 0xFFFF;
  htim5.Init.ClockDivision = TIM_CLOCKDIVISION_DIV1;
  htim5.Init.AutoReloadPreload = TIM_AUTORELOAD_PRELOAD_DISABLE;
  if (HAL_TIM_Base_Init(&htim5) != HAL_OK)
  {
    _Error_Handler(__FILE__, __LINE__);
  }

  sClockSourceConfig.ClockSource = TIM_CLOCKSOURCE_INTERNAL;
  if (HAL_TIM_ConfigClockSource(&htim5, &sClockSourceConfig) != HAL_OK)
  {
    _Error_Handler(__FILE__, __LINE__);
  }

  if (HAL_TIM_IC_Init(&htim5) != HAL_OK)
  {
    _Error_Handler(__FILE__, __LINE__);
  }

  sMasterConfig.MasterOutputTrigger = TIM_TRGO_RESET;
  sMasterConfig.MasterSlaveMode = TIM_MASTERSLAVEMODE_DISABLE;
  if (HAL_TIMEx_MasterConfigSynchronization(&htim5, &sMasterConfig) != HAL_OK)
  {
    _Error_Handler(__FILE__, __LINE__);
  }

  sConfigIC.ICPolarity = TIM_INPUTCHANNELPOLARITY_RISING;
  sConfigIC.ICSelection = TIM_ICSELECTION_DIRECTTI;
  sConfigIC.ICPrescaler = TIM_ICPSC_DIV1;
  sConfigIC.ICFilter = 0;
  if (HAL_TIM_IC_ConfigChannel(&htim5, &sConfigIC, TIM_CHANNEL_1) != HAL_OK)
  {
    _Error_Handler(__FILE__, __LINE__);
  }

}

/* UART4 init function */
static void MX_UART4_Init(void)
{

  huart4.Instance = UART4;
  huart4.Init.BaudRate = 115200;
  huart4.Init.WordLength = UART_WORDLENGTH_8B;
  huart4.Init.StopBits = UART_STOPBITS_1;
  huart4.Init.Parity = UART_PARITY_NONE;
  huart4.Init.Mode = UART_MODE_TX_RX;
  huart4.Init.HwFlowCtl = UART_HWCONTROL_NONE;
  huart4.Init.OverSampling = UART_OVERSAMPLING_16;
  if (HAL_UART_Init(&huart4) != HAL_OK)
  {
    _Error_Handler(__FILE__, __LINE__);
  }

}

/* UART5 init function */
static void MX_UART5_Init(void)
{

  huart5.Instance = UART5;
  huart5.Init.BaudRate = 115200;
  huart5.Init.WordLength = UART_WORDLENGTH_8B;
  huart5.Init.StopBits = UART_STOPBITS_1;
  huart5.Init.Parity = UART_PARITY_NONE;
  huart5.Init.Mode = UART_MODE_TX_RX;
  huart5.Init.HwFlowCtl = UART_HWCONTROL_NONE;
  huart5.Init.OverSampling = UART_OVERSAMPLING_16;
  if (HAL_HalfDuplex_Init(&huart5) != HAL_OK)
  {
    _Error_Handler(__FILE__, __LINE__);
  }

}

/* USER CODE BEGIN 4 */
static void MX_GPIO_Init(void)
{

  GPIO_InitTypeDef GPIO_InitStruct;

  /* GPIO Ports Clock Enable */
  __HAL_RCC_GPIOE_CLK_ENABLE();
  __HAL_RCC_GPIOC_CLK_ENABLE();
  __HAL_RCC_GPIOA_CLK_ENABLE();
  __HAL_RCC_GPIOB_CLK_ENABLE();
  __HAL_RCC_GPIOD_CLK_ENABLE();

  /*Configure GPIO pin Output Level */
  HAL_GPIO_WritePin(GPIOE, BrakeLight_Pin|Aux_1_Pin|Aux_2_Pin|Aux_3_Pin
                          |WS_Pin|SE1_Pin|SE2_Pin|DRV_reset_Pin
                          |EM_en_Pin, GPIO_PIN_RESET);

  /*Configure GPIO pin Output Level */
  HAL_GPIO_WritePin(GPIOC, RTDS_Pin|SDBR_Pin|SDBL_Pin|SEL0_Pin
                          |ECUA_en_Pin|ECUF_en_Pin, GPIO_PIN_RESET);

  /*Configure GPIO pin Output Level */
  HAL_GPIO_WritePin(GPIOB, SEL1_Pin|LED2_Pin|ECUMCF_en_Pin|LED3_Pin
                          |Charge_en_Pin, GPIO_PIN_RESET);

  /*Configure GPIO pin Output Level */
  HAL_GPIO_WritePin(GPIOD, LED7_Pin|LED6_Pin|LED5_Pin|LED4_Pin
                          |TSALL_test_Pin|SDC_complete_Pin|CS_MOD1_Pin|CS_MOD2_Pin
                          |CS_MOD3_Pin|ECUMCR_en_Pin, GPIO_PIN_RESET);

  /*Configure GPIO pin Output Level */
  HAL_GPIO_WritePin(GPIOA, SDC_CS_Pin|PTRCS_Pin|PTLCS_Pin|Bat_cs_Pin
                          |LED1_Pin, GPIO_PIN_RESET);

  /*Configure GPIO pins : BrakeLight_Pin Aux_1_Pin Aux_2_Pin Aux_3_Pin
                           WS_Pin SE1_Pin SE2_Pin DRV_reset_Pin
                           EM_en_Pin */
  GPIO_InitStruct.Pin = BrakeLight_Pin|Aux_1_Pin|Aux_2_Pin|Aux_3_Pin
                          |WS_Pin|SE1_Pin|SE2_Pin|DRV_reset_Pin
                          |EM_en_Pin;
  GPIO_InitStruct.Mode = GPIO_MODE_OUTPUT_PP;
  GPIO_InitStruct.Speed = GPIO_SPEED_FREQ_LOW;
  HAL_GPIO_Init(GPIOE, &GPIO_InitStruct);

  /*Configure GPIO pins : RTDS_Pin SDBR_Pin SDBL_Pin SEL0_Pin
                           ECUA_en_Pin ECUF_en_Pin */
  GPIO_InitStruct.Pin = RTDS_Pin|SDBR_Pin|SDBL_Pin|SEL0_Pin
                          |ECUA_en_Pin|ECUF_en_Pin;
  GPIO_InitStruct.Mode = GPIO_MODE_OUTPUT_PP;
  GPIO_InitStruct.Speed = GPIO_SPEED_FREQ_LOW;
  HAL_GPIO_Init(GPIOC, &GPIO_InitStruct);

  /*Configure GPIO pins : SEL1_Pin LED2_Pin ECUMCF_en_Pin LED3_Pin
                           Charge_en_Pin */
  GPIO_InitStruct.Pin = SEL1_Pin|LED2_Pin|ECUMCF_en_Pin|LED3_Pin
                          |Charge_en_Pin;
  GPIO_InitStruct.Mode = GPIO_MODE_OUTPUT_PP;
  GPIO_InitStruct.Speed = GPIO_SPEED_FREQ_LOW;
  HAL_GPIO_Init(GPIOB, &GPIO_InitStruct);

  /*Configure GPIO pins : Fault_WP_Pin Fault_Fan1_2_Pin Fault_EM__Fan3_Pin */
  GPIO_InitStruct.Pin = Fault_WP_Pin|Fault_Fan1_2_Pin|Fault_EM__Fan3_Pin;
  GPIO_InitStruct.Mode = GPIO_MODE_INPUT;
  GPIO_InitStruct.Pull = GPIO_NOPULL;
  HAL_GPIO_Init(GPIOE, &GPIO_InitStruct);

  /*Configure GPIO pins : Diag1_Pin Diag2_Pin Det3_Pin */
  GPIO_InitStruct.Pin = Diag1_Pin|Diag2_Pin|Det3_Pin;
  GPIO_InitStruct.Mode = GPIO_MODE_INPUT;
  GPIO_InitStruct.Pull = GPIO_NOPULL;
  HAL_GPIO_Init(GPIOB, &GPIO_InitStruct);

  /*Configure GPIO pins : Charge_status_Pin Charge_pow_ok_Pin Det1_Pin Det2_Pin */
  GPIO_InitStruct.Pin = Charge_status_Pin|Charge_pow_ok_Pin|Det1_Pin|Det2_Pin;
  GPIO_InitStruct.Mode = GPIO_MODE_INPUT;
  GPIO_InitStruct.Pull = GPIO_NOPULL;
  HAL_GPIO_Init(GPIOD, &GPIO_InitStruct);

  /*Configure GPIO pins : LED7_Pin LED6_Pin LED5_Pin LED4_Pin
                           TSALL_test_Pin SDC_complete_Pin CS_MOD1_Pin CS_MOD2_Pin
                           CS_MOD3_Pin ECUMCR_en_Pin */
  GPIO_InitStruct.Pin = LED7_Pin|LED6_Pin|LED5_Pin|LED4_Pin
                          |TSALL_test_Pin|SDC_complete_Pin|CS_MOD1_Pin|CS_MOD2_Pin
                          |CS_MOD3_Pin|ECUMCR_en_Pin;
  GPIO_InitStruct.Mode = GPIO_MODE_OUTPUT_PP;
  GPIO_InitStruct.Speed = GPIO_SPEED_FREQ_LOW;
  HAL_GPIO_Init(GPIOD, &GPIO_InitStruct);

  /*Configure GPIO pins : SDC_CS_Pin PTRCS_Pin PTLCS_Pin Bat_cs_Pin
                           LED1_Pin */
  GPIO_InitStruct.Pin = SDC_CS_Pin|PTRCS_Pin|PTLCS_Pin|Bat_cs_Pin
                          |LED1_Pin;
  GPIO_InitStruct.Mode = GPIO_MODE_OUTPUT_PP;
  GPIO_InitStruct.Speed = GPIO_SPEED_FREQ_LOW;
  HAL_GPIO_Init(GPIOA, &GPIO_InitStruct);

}

static void MX_DMA_Init(void)
{
  /* DMA controller clock enable */
  __HAL_RCC_DMA1_CLK_ENABLE();

  /* DMA interrupt init */
  /* DMA1_Channel1_IRQn interrupt configuration */
  HAL_NVIC_SetPriority(DMA1_Channel1_IRQn, 10, 10);
  HAL_NVIC_EnableIRQ(DMA1_Channel1_IRQn);

}
/* USER CODE END 4 */

void _Error_Handler(char *file, int line)
{
  while(1)
  {
  }
}

/************************ (C) COPYRIGHT STMicroelectronics *****END OF FILE****/
